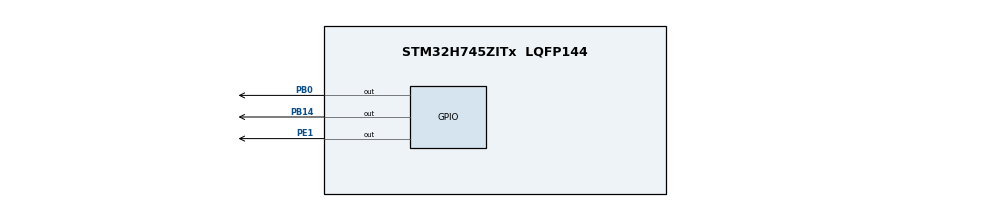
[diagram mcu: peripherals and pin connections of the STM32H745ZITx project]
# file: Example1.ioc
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CortexM4.IPs=FATFS_M4\:I,FREERTOS_M4\:I,IWDG2\:I,RCC,WWDG2\:I,DMA,BDMA,MDMA,NVIC2\:I,USART3,ETH,DEBUG,USB_DEVICE_M4\:I,USB_HOST_M4\:I,PDM2PCM_M4\:I,PWR,RESMGR_UTILITY,SYS_M4\:I,CORTEX_M4\:I,OPENAMP_M4\:I,VREFBUF
CortexM7.IPs=FATFS_M7\:I,FREERTOS_M7\:I,IWDG1\:I,RCC\:I,WWDG1\:I,DMA\:I,BDMA\:I,MDMA\:I,NVIC1\:I,SYS\:I,USART3\:I,USB_OTG_FS\:I,ETH\:I,CORTEX_M7\:I,DEBUG\:I,USB_DEVICE_M7\:I,USB_HOST_M7\:I,PDM2PCM_M7\:I,PWR\:I,RESMGR_UTILITY\:I,OPENAMP_M7\:I,VREFBUF\:I,TIM6\:I
CortexM7.Pins=PB0,PB14,PE1
FREERTOS_M7.Tasks01=myTask01,24,128,StartDefaultTask,Default,NULL,Dynamic,NULL,NULL;myTask02,16,128,StartTask02,Default,NULL,Dynamic,NULL,NULL
Mcu.Family=STM32H7
Mcu.Name=STM32H745ZITx
Mcu.Package=LQFP144
NVIC1.PriorityGroup=NVIC_PRIORITYGROUP_4
NVIC1.TIM6_DAC_IRQn=true\:15\:0\:false\:false\:true\:false\:false\:true\:true
NVIC1.TimeBase=TIM6_DAC_IRQn
NVIC1.TimeBaseIP=TIM6
NVIC2.PriorityGroup=NVIC_PRIORITYGROUP_4
PB0.PinAttribute=CortexM7
PB0.Signal=GPIO_Output
PB14.PinAttribute=CortexM7
PB14.Signal=GPIO_Output
PE1.PinAttribute=CortexM7
PE1.Signal=GPIO_Output
ProjectManager.HeapSize=M4-0x200,M7-0x200
ProjectManager.StackSize=M4-0x400,M7-0x400
ProjectManager.TargetToolchain=STM32CubeIDE
RCC.ADCFreq_Value=129000000
RCC.APB1Freq_Value=40000000
RCC.APB2Freq_Value=40000000
RCC.APB3Freq_Value=40000000
RCC.APB4Freq_Value=40000000
RCC.CortexFreq_Value=80000000
RCC.D1PPRE=RCC_APB3_DIV2
RCC.D2PPRE1=RCC_APB1_DIV2
RCC.D2PPRE2=RCC_APB2_DIV2
RCC.D3PPRE=RCC_APB4_DIV2
RCC.DIVM1=4
RCC.DIVM3=1
RCC.DIVN1=10
RCC.DIVN3=24
RCC.DIVQ3=4
RCC.HCLKFreq_Value=80000000
RCC.HSE_VALUE=8000000
RCC.PLL2FRACN=0
RCC.PLL3FRACN=0
RCC.PLLFRACN=0
RCC.SYSCLKFreq_VALUE=80000000
RCC.SYSCLKSource=RCC_SYSCLKSOURCE_PLLCLK
RCC.SupplySource=PWR_DIRECT_SMPS_SUPPLY
RCC.USBCLockSelection=RCC_USBCLKSOURCE_PLL3
RCC.USBFreq_Value=384000000
VP_FREERTOS_M7_VS_CMSIS_V2.Mode=CMSIS_V2
VP_SYS_M4_VS_Systick.Mode=SysTick
VP_SYS_VS_tim6.Mode=TIM6
board=NUCLEO-H745ZI-Q

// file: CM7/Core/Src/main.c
/* USER CODE BEGIN Header */
/**
  ******************************************************************************
  * @file           : main.c
  * @brief          : Main program body
  ******************************************************************************
  * @attention
  *
  * Copyright (c) 2022 STMicroelectronics.
  * All rights reserved.
  *
  * This software is licensed under terms that can be found in the LICENSE file
  * in the root directory of this software component.
  * If no LICENSE file comes with this software, it is provided AS-IS.
  *
  ******************************************************************************
  */
/* USER CODE END Header */
#include "main.h"
#include "cmsis_os.h"

/* USER CODE BEGIN PD */

#ifndef HSEM_ID_0
#define HSEM_ID_0 (0U) /* HW semaphore 0*/
#endif
/* USER CODE END PD */

/* Definitions for myTask01 */
osThreadId_t myTask01Handle;
const osThreadAttr_t myTask01_attributes = {
  .name = "myTask01",
  .stack_size = 128 * 4,
  .priority = (osPriority_t) osPriorityNormal,
};
/* Definitions for myTask02 */
osThreadId_t myTask02Handle;
const osThreadAttr_t myTask02_attributes = {
  .name = "myTask02",
  .stack_size = 128 * 4,
  .priority = (osPriority_t) osPriorityBelowNormal,
};

void SystemClock_Config(void);
static void MX_GPIO_Init(void);
void StartDefaultTask(void *argument);
void StartTask02(void *argument);

int main(void)
{
/* USER CODE BEGIN Boot_Mode_Sequence_0 */
  int32_t timeout;
/* USER CODE END Boot_Mode_Sequence_0 */

/* USER CODE BEGIN Boot_Mode_Sequence_1 */
  /* Wait until CPU2 boots and enters in stop mode or timeout*/
  timeout = 0xFFFF;
  while((__HAL_RCC_GET_FLAG(RCC_FLAG_D2CKRDY) != RESET) && (timeout-- > 0));
  if ( timeout < 0 )
  {
  Error_Handler();
  }
/* USER CODE END Boot_Mode_Sequence_1 */
  /* MCU Configuration--------------------------------------------------------*/

  /* Reset of all peripherals, Initializes the Flash interface and the Systick. */
  HAL_Init();

  /* Configure the system clock */
  SystemClock_Config();
/* USER CODE BEGIN Boot_Mode_Sequence_2 */
/* When system initialization is finished, Cortex-M7 will release Cortex-M4 by means of
HSEM notification */
/*HW semaphore Clock enable*/
__HAL_RCC_HSEM_CLK_ENABLE();
/*Take HSEM */
HAL_HSEM_FastTake(HSEM_ID_0);
/*Release HSEM in order to notify the CPU2(CM4)*/
HAL_HSEM_Release(HSEM_ID_0,0);
/* wait until CPU2 wakes up from stop mode */
timeout = 0xFFFF;
while((__HAL_RCC_GET_FLAG(RCC_FLAG_D2CKRDY) == RESET) && (timeout-- > 0));
if ( timeout < 0 )
{
Error_Handler();
}
/* USER CODE END Boot_Mode_Sequence_2 */

  /* Initialize all configured peripherals */
  MX_GPIO_Init();

  /* Init scheduler */
  osKernelInitialize();

  /* Create the thread(s) */
  /* creation of myTask01 */
  myTask01Handle = osThreadNew(StartDefaultTask, NULL, &myTask01_attributes);

  /* creation of myTask02 */
  myTask02Handle = osThreadNew(StartTask02, NULL, &myTask02_attributes);

  /* Start scheduler */
  osKernelStart();

  /* We should never get here as control is now taken by the scheduler */
  /* Infinite loop */
  while (1)
  {

  }
}

void SystemClock_Config(void)
{
  RCC_OscInitTypeDef RCC_OscInitStruct = {0};
  RCC_ClkInitTypeDef RCC_ClkInitStruct = {0};

  /** Supply configuration update enable
  */
  HAL_PWREx_ConfigSupply(PWR_DIRECT_SMPS_SUPPLY);

  /** Configure the main internal regulator output voltage
  */
  __HAL_PWR_VOLTAGESCALING_CONFIG(PWR_REGULATOR_VOLTAGE_SCALE3);

  while(!__HAL_PWR_GET_FLAG(PWR_FLAG_VOSRDY)) {}

  /** Initializes the RCC Oscillators according to the specified parameters
  * in the RCC_OscInitTypeDef structure.
  */
  RCC_OscInitStruct.OscillatorType = RCC_OSCILLATORTYPE_HSI;
  RCC_OscInitStruct.HSIState = RCC_HSI_DIV1;
  RCC_OscInitStruct.HSICalibrationValue = RCC_HSICALIBRATION_DEFAULT;
  RCC_OscInitStruct.PLL.PLLState = RCC_PLL_ON;
  RCC_OscInitStruct.PLL.PLLSource = RCC_PLLSOURCE_HSI;
  RCC_OscInitStruct.PLL.PLLM = 4;
  RCC_OscInitStruct.PLL.PLLN = 10;
  RCC_OscInitStruct.PLL.PLLP = 2;
  RCC_OscInitStruct.PLL.PLLQ = 2;
  RCC_OscInitStruct.PLL.PLLR = 2;
  RCC_OscInitStruct.PLL.PLLRGE = RCC_PLL1VCIRANGE_3;
  RCC_OscInitStruct.PLL.PLLVCOSEL = RCC_PLL1VCOMEDIUM;
  RCC_OscInitStruct.PLL.PLLFRACN = 0;
  if (HAL_RCC_OscConfig(&RCC_OscInitStruct) != HAL_OK)
  {
    Error_Handler();
  }

  /** Initializes the CPU, AHB and APB buses clocks
  */
  RCC_ClkInitStruct.ClockType = RCC_CLOCKTYPE_HCLK|RCC_CLOCKTYPE_SYSCLK
                              |RCC_CLOCKTYPE_PCLK1|RCC_CLOCKTYPE_PCLK2
                              |RCC_CLOCKTYPE_D3PCLK1|RCC_CLOCKTYPE_D1PCLK1;
  RCC_ClkInitStruct.SYSCLKSource = RCC_SYSCLKSOURCE_PLLCLK;
  RCC_ClkInitStruct.SYSCLKDivider = RCC_SYSCLK_DIV1;
  RCC_ClkInitStruct.AHBCLKDivider = RCC_HCLK_DIV1;
  RCC_ClkInitStruct.APB3CLKDivider = RCC_APB3_DIV2;
  RCC_ClkInitStruct.APB1CLKDivider = RCC_APB1_DIV2;
  RCC_ClkInitStruct.APB2CLKDivider = RCC_APB2_DIV2;
  RCC_ClkInitStruct.APB4CLKDivider = RCC_APB4_DIV2;

  if (HAL_RCC_ClockConfig(&RCC_ClkInitStruct, FLASH_LATENCY_1) != HAL_OK)
  {
    Error_Handler();
  }
}

static void MX_GPIO_Init(void)
{
  GPIO_InitTypeDef GPIO_InitStruct = {0};

  /* GPIO Ports Clock Enable */
  __HAL_RCC_GPIOB_CLK_ENABLE();
  __HAL_RCC_GPIOE_CLK_ENABLE();

  /*Configure GPIO pin Output Level */
  HAL_GPIO_WritePin(GPIOB, GPIO_PIN_0|GPIO_PIN_14, GPIO_PIN_RESET);

  /*Configure GPIO pin Output Level */
  HAL_GPIO_WritePin(GPIOE, GPIO_PIN_1, GPIO_PIN_RESET);

  /*Configure GPIO pins : PB0 PB14 */
  GPIO_InitStruct.Pin = GPIO_PIN_0|GPIO_PIN_14;
  GPIO_InitStruct.Mode = GPIO_MODE_OUTPUT_PP;
  GPIO_InitStruct.Pull = GPIO_NOPULL;
  GPIO_InitStruct.Speed = GPIO_SPEED_FREQ_LOW;
  HAL_GPIO_Init(GPIOB, &GPIO_InitStruct);

  /*Configure GPIO pin : PE1 */
  GPIO_InitStruct.Pin = GPIO_PIN_1;
  GPIO_InitStruct.Mode = GPIO_MODE_OUTPUT_PP;
  GPIO_InitStruct.Pull = GPIO_NOPULL;
  GPIO_InitStruct.Speed = GPIO_SPEED_FREQ_LOW;
  HAL_GPIO_Init(GPIOE, &GPIO_InitStruct);

}

void StartDefaultTask(void *argument)
{
  /* USER CODE BEGIN 5 */
  /* Infinite loop */
  for(;;)
  {
	  HAL_GPIO_TogglePin(GPIOE, GPIO_PIN_1);
	  HAL_GPIO_TogglePin(GPIOB, GPIO_PIN_0);
	  vTaskDelay(500 / portTICK_PERIOD_MS);
  }
  /* USER CODE END 5 */
}

void StartTask02(void *argument)
{
  /* USER CODE BEGIN StartTask02 */
  /* Infinite loop */
  for(;;)
  {
	  HAL_GPIO_TogglePin(GPIOB, GPIO_PIN_14);
	  vTaskDelay(750 / portTICK_PERIOD_MS);
  }
  /* USER CODE END StartTask02 */
}

void HAL_TIM_PeriodElapsedCallback(TIM_HandleTypeDef *htim)
{
  if (htim->Instance == TIM6) {
    HAL_IncTick();
  }
}

void Error_Handler(void)
{
  __disable_irq();
  while (1)
  {
  }
}
